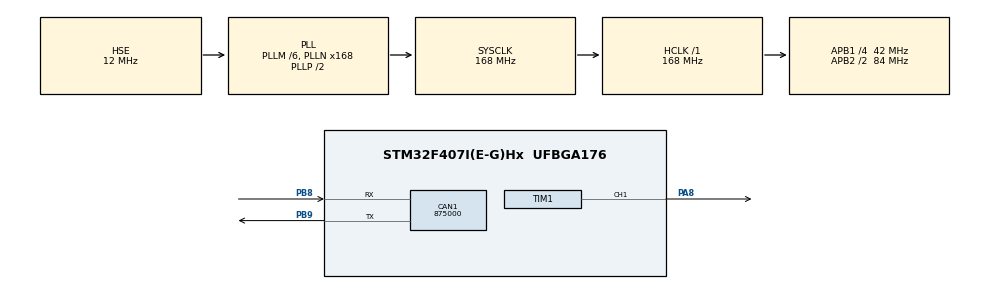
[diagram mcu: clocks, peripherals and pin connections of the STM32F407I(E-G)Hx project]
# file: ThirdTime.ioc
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CAN1.BS1=CAN_BS1_1TQ
CAN1.BS2=CAN_BS2_1TQ
CAN1.CalculateBaudRate=875000
CAN1.CalculateTimeBit=1142
CAN1.CalculateTimeQuantum=380.95238095238096
Mcu.Family=STM32F4
Mcu.Name=STM32F407I(E-G)Hx
Mcu.Package=UFBGA176
NVIC.PriorityGroup=NVIC_PRIORITYGROUP_4
PA13.Mode=Serial_Wire
PA13.Signal=SYS_JTMS-SWDIO
PA14.Mode=Serial_Wire
PA14.Signal=SYS_JTCK-SWCLK
PA8.Signal=S_TIM1_CH1
PB8.Mode=CAN_Activate
PB8.Signal=CAN1_RX
PB9.Mode=CAN_Activate
PB9.Signal=CAN1_TX
PH0-OSC_IN.Mode=HSE-External-Oscillator
PH0-OSC_IN.Signal=RCC_OSC_IN
PH1-OSC_OUT.Mode=HSE-External-Oscillator
PH1-OSC_OUT.Signal=RCC_OSC_OUT
ProjectManager.HeapSize=0x200
ProjectManager.StackSize=0x400
ProjectManager.TargetToolchain=MDK-ARM V5.32
RCC.48MHZClocksFreq_Value=84000000
RCC.AHBFreq_Value=168000000
RCC.APB1CLKDivider=RCC_HCLK_DIV4
RCC.APB1Freq_Value=42000000
RCC.APB1TimFreq_Value=84000000
RCC.APB2CLKDivider=RCC_HCLK_DIV2
RCC.APB2Freq_Value=84000000
RCC.APB2TimFreq_Value=168000000
RCC.CortexFreq_Value=168000000
RCC.HCLKFreq_Value=168000000
RCC.HSE_VALUE=12000000
RCC.HSI_VALUE=16000000
RCC.LSE_VALUE=32768
RCC.PLLM=6
RCC.PLLN=168
RCC.PLLSourceVirtual=RCC_PLLSOURCE_HSE
RCC.SYSCLKFreq_VALUE=168000000
RCC.SYSCLKSource=RCC_SYSCLKSOURCE_PLLCLK
RCC.VCOOutputFreq_Value=336000000
SH.S_TIM1_CH1.0=TIM1_CH1,PWM Generation1 CH1
TIM1.Channel-PWM\ Generation1\ CH1=TIM_CHANNEL_1
TIM1.Period=10000-1
TIM1.Prescaler=16800-1
board=custom

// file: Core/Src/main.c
/* USER CODE BEGIN Header */
/**
  ******************************************************************************
  * @file           : main.c
  * @brief          : Main program body
  ******************************************************************************
  * @attention
  *
  * Copyright (c) 2023 STMicroelectronics.
  * All rights reserved.
  *
  * This software is licensed under terms that can be found in the LICENSE file
  * in the root directory of this software component.
  * If no LICENSE file comes with this software, it is provided AS-IS.
  *
  ******************************************************************************
  */
/* USER CODE END Header */
#include "main.h"
#include "can.h"
#include "tim.h"
#include "gpio.h"

/* USER CODE BEGIN Includes */
#include "PIDclass.h"
/* USER CODE END Includes */

void SystemClock_Config(void);
/* USER CODE BEGIN PFP */
void motorgo();
void motorspeed(uint32_t s);
void cansend(int16_t motor1,int16_t motor2,int16_t motor3,int16_t motor4);
/* USER CODE END PFP */

int main(void)
{

  /* MCU Configuration--------------------------------------------------------*/

  /* Reset of all peripherals, Initializes the Flash interface and the Systick. */
  HAL_Init();

  /* Configure the system clock */
  SystemClock_Config();

  /* Initialize all configured peripherals */
  MX_GPIO_Init();
  MX_CAN1_Init();
  MX_TIM1_Init();
  /* USER CODE BEGIN 2 */
    HAL_TIM_Base_Init(&htim1);
    HAL_TIM_PWM_Start(&htim1,TIM_CHANNEL_1);

  /* USER CODE END 2 */

  /* Infinite loop */
  while (1)
  {

  }
}

void SystemClock_Config(void)
{
  RCC_OscInitTypeDef RCC_OscInitStruct = {0};
  RCC_ClkInitTypeDef RCC_ClkInitStruct = {0};

  /** Configure the main internal regulator output voltage
  */
  __HAL_RCC_PWR_CLK_ENABLE();
  __HAL_PWR_VOLTAGESCALING_CONFIG(PWR_REGULATOR_VOLTAGE_SCALE1);

  /** Initializes the RCC Oscillators according to the specified parameters
  * in the RCC_OscInitTypeDef structure.
  */
  RCC_OscInitStruct.OscillatorType = RCC_OSCILLATORTYPE_HSE;
  RCC_OscInitStruct.HSEState = RCC_HSE_ON;
  RCC_OscInitStruct.PLL.PLLState = RCC_PLL_ON;
  RCC_OscInitStruct.PLL.PLLSource = RCC_PLLSOURCE_HSE;
  RCC_OscInitStruct.PLL.PLLM = 6;
  RCC_OscInitStruct.PLL.PLLN = 168;
  RCC_OscInitStruct.PLL.PLLP = RCC_PLLP_DIV2;
  RCC_OscInitStruct.PLL.PLLQ = 4;
  if (HAL_RCC_OscConfig(&RCC_OscInitStruct) != HAL_OK)
  {
    Error_Handler();
  }

  /** Initializes the CPU, AHB and APB buses clocks
  */
  RCC_ClkInitStruct.ClockType = RCC_CLOCKTYPE_HCLK|RCC_CLOCKTYPE_SYSCLK
                              |RCC_CLOCKTYPE_PCLK1|RCC_CLOCKTYPE_PCLK2;
  RCC_ClkInitStruct.SYSCLKSource = RCC_SYSCLKSOURCE_PLLCLK;
  RCC_ClkInitStruct.AHBCLKDivider = RCC_SYSCLK_DIV1;
  RCC_ClkInitStruct.APB1CLKDivider = RCC_HCLK_DIV4;
  RCC_ClkInitStruct.APB2CLKDivider = RCC_HCLK_DIV2;

  if (HAL_RCC_ClockConfig(&RCC_ClkInitStruct, FLASH_LATENCY_5) != HAL_OK)
  {
    Error_Handler();
  }
}

/* USER CODE BEGIN 4 */

//任务一：对小球进行速度控制
//可用条件：已知小球的实时速度，并且可施加一个力来改变小球的速度
//PID目标值：需要小球达到的速度
//PID反馈值：小球的实时速度
//PID输出值：施加在小球上的力
//分析：小球加速度是小球速度的低阶物理量，而施加的力正比于小球加速度

void PIDContorller()
{

}
void motorgo(){
    for(int i=5;i<10;i++){
        __HAL_TIM_SET_COMPARE(&htim1,TIM_CHANNEL_1,i);
        HAL_Delay(100);
    }
}

void motorspeed(uint32_t s){
    __HAL_TIM_SET_COMPARE(&htim1,TIM_CHANNEL_1,s);
}

void cansend(int16_t motor1,int16_t motor2,int16_t motor3,int16_t motor4){
    uint32_t  CAN_TX_MAILBOX01;
    CAN_TxHeaderTypeDef tx_header;
    tx_header.StdId=0x200;
    tx_header.IDE=CAN_ID_STD;
    tx_header.RTR=CAN_RTR_DATA;
    tx_header.DLC=0x08;

    uint8_t send_data[8];
    send_data[0]=motor1>>8;
    send_data[1]=motor1;
    send_data[2]=motor2>>8;
    send_data[3]=motor2;
    send_data[4]=motor3>>8;
    send_data[5]=motor3;
    send_data[6]=motor4>>8;
    send_data[7]=motor4;

    HAL_CAN_AddTxMessage(&hcan1,&tx_header,&send_data,(uint32_t*)CAN_TX_MAILBOX01);
}
/* USER CODE END 4 */

void Error_Handler(void)
{
  __disable_irq();
  while (1)
  {
  }
}
